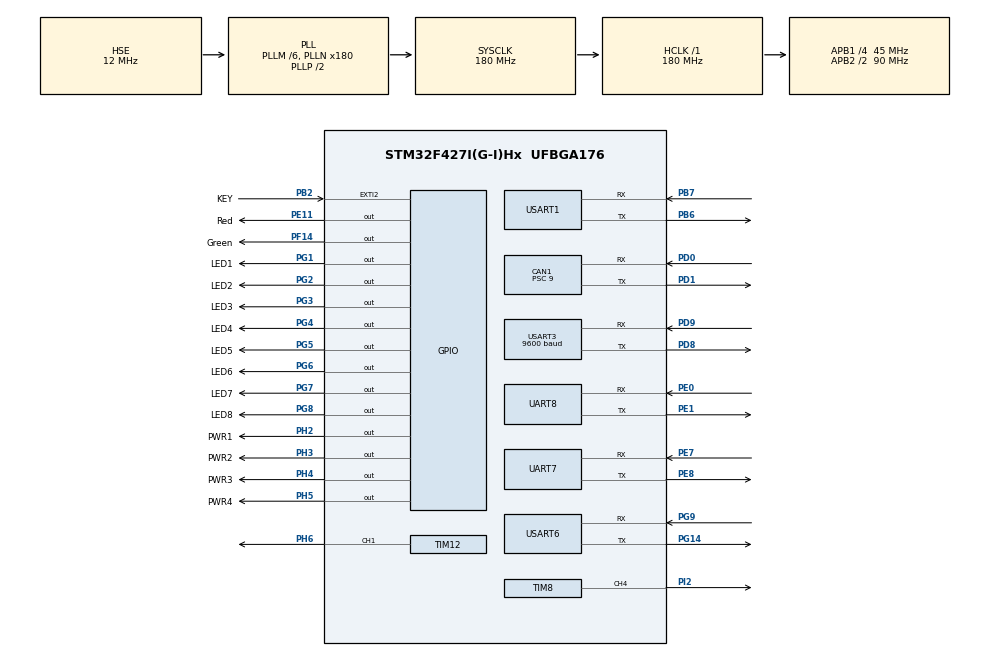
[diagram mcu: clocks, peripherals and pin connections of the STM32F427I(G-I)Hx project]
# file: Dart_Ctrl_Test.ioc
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CAN1.ABOM=ENABLE
CAN1.BS1=CAN_BS1_2TQ
CAN1.BS2=CAN_BS2_2TQ
CAN1.CalculateBaudRate=1000000
CAN1.CalculateTimeBit=1000
CAN1.CalculateTimeQuantum=200.0
CAN1.Prescaler=9
Dma.Request0=UART7_RX
Dma.Request1=UART7_TX
Dma.Request2=USART3_TX
Dma.Request3=USART6_RX
Dma.UART7_RX.0.Direction=DMA_PERIPH_TO_MEMORY
Dma.UART7_RX.0.FIFOMode=DMA_FIFOMODE_DISABLE
Dma.UART7_RX.0.Instance=DMA1_Stream3
Dma.UART7_RX.0.MemDataAlignment=DMA_MDATAALIGN_BYTE
Dma.UART7_RX.0.MemInc=DMA_MINC_ENABLE
Dma.UART7_RX.0.Mode=DMA_NORMAL
Dma.UART7_RX.0.PeriphDataAlignment=DMA_PDATAALIGN_BYTE
Dma.UART7_RX.0.PeriphInc=DMA_PINC_DISABLE
Dma.UART7_RX.0.Priority=DMA_PRIORITY_LOW
Dma.UART7_TX.1.Direction=DMA_MEMORY_TO_PERIPH
Dma.UART7_TX.1.FIFOMode=DMA_FIFOMODE_DISABLE
Dma.UART7_TX.1.Instance=DMA1_Stream1
Dma.UART7_TX.1.MemDataAlignment=DMA_MDATAALIGN_BYTE
Dma.UART7_TX.1.MemInc=DMA_MINC_ENABLE
Dma.UART7_TX.1.Mode=DMA_NORMAL
Dma.UART7_TX.1.PeriphDataAlignment=DMA_PDATAALIGN_BYTE
Dma.UART7_TX.1.PeriphInc=DMA_PINC_DISABLE
Dma.UART7_TX.1.Priority=DMA_PRIORITY_LOW
Dma.USART3_TX.2.Direction=DMA_MEMORY_TO_PERIPH
Dma.USART3_TX.2.FIFOMode=DMA_FIFOMODE_DISABLE
Dma.USART3_TX.2.Instance=DMA1_Stream4
Dma.USART3_TX.2.MemDataAlignment=DMA_MDATAALIGN_BYTE
Dma.USART3_TX.2.MemInc=DMA_MINC_ENABLE
Dma.USART3_TX.2.Mode=DMA_NORMAL
Dma.USART3_TX.2.PeriphDataAlignment=DMA_PDATAALIGN_BYTE
Dma.USART3_TX.2.PeriphInc=DMA_PINC_DISABLE
Dma.USART3_TX.2.Priority=DMA_PRIORITY_LOW
Dma.USART6_RX.3.Direction=DMA_PERIPH_TO_MEMORY
Dma.USART6_RX.3.FIFOMode=DMA_FIFOMODE_DISABLE
Dma.USART6_RX.3.Instance=DMA2_Stream1
Dma.USART6_RX.3.MemDataAlignment=DMA_MDATAALIGN_BYTE
Dma.USART6_RX.3.MemInc=DMA_MINC_ENABLE
Dma.USART6_RX.3.Mode=DMA_NORMAL
Dma.USART6_RX.3.PeriphDataAlignment=DMA_PDATAALIGN_BYTE
Dma.USART6_RX.3.PeriphInc=DMA_PINC_DISABLE
Dma.USART6_RX.3.Priority=DMA_PRIORITY_LOW
FREERTOS.Tasks01=defaultTask,24,128,StartDefaultTask,Default,NULL,Dynamic,NULL,NULL
FREERTOS.configENABLE_FPU=1
Mcu.Family=STM32F4
Mcu.Name=STM32F427I(G-I)Hx
Mcu.Package=UFBGA176
NVIC.CAN1_RX0_IRQn=true\:5\:0\:false\:false\:true\:true\:true\:true\:true
NVIC.CAN1_RX1_IRQn=true\:5\:0\:false\:false\:true\:true\:true\:true\:true
NVIC.CAN1_SCE_IRQn=true\:5\:0\:false\:false\:true\:true\:true\:true\:true
NVIC.CAN1_TX_IRQn=true\:5\:0\:false\:false\:true\:true\:true\:true\:true
NVIC.DMA1_Stream1_IRQn=true\:5\:0\:false\:false\:true\:true\:false\:true\:true
NVIC.DMA1_Stream3_IRQn=true\:5\:0\:false\:false\:true\:true\:false\:true\:true
NVIC.DMA1_Stream4_IRQn=true\:5\:0\:false\:false\:true\:true\:false\:true\:true
NVIC.DMA2_Stream1_IRQn=true\:5\:0\:false\:false\:true\:true\:false\:true\:true
NVIC.PriorityGroup=NVIC_PRIORITYGROUP_4
NVIC.TIM4_IRQn=true\:15\:0\:true\:false\:true\:false\:false\:true\:true
NVIC.TimeBase=TIM4_IRQn
NVIC.TimeBaseIP=TIM4
NVIC.UART7_IRQn=true\:5\:0\:false\:false\:true\:true\:true\:true\:true
NVIC.UART8_IRQn=true\:5\:0\:false\:false\:true\:true\:true\:true\:true
NVIC.USART3_IRQn=true\:5\:0\:false\:false\:true\:true\:true\:true\:true
NVIC.USART6_IRQn=true\:5\:0\:false\:false\:true\:true\:true\:true\:true
PA13.Mode=Serial_Wire
PA13.Signal=SYS_JTMS-SWDIO
PA14.Mode=Serial_Wire
PA14.Signal=SYS_JTCK-SWCLK
PB2/BOOT1.GPIO_Label=KEY
PB2/BOOT1.GPIO_ModeDefaultEXTI=GPIO_MODE_IT_RISING
PB2/BOOT1.GPIO_PuPd=GPIO_PULLDOWN
PB2/BOOT1.Signal=GPXTI2
PB6.Mode=Asynchronous
PB6.Signal=USART1_TX
PB7.Mode=Asynchronous
PB7.Signal=USART1_RX
PC14/OSC32_IN.Mode=LSE-External-Oscillator
PC14/OSC32_IN.Signal=RCC_OSC32_IN
PC15/OSC32_OUT.Mode=LSE-External-Oscillator
PC15/OSC32_OUT.Signal=RCC_OSC32_OUT
PD0.Mode=CAN_Activate
PD0.Signal=CAN1_RX
PD1.Mode=CAN_Activate
PD1.Signal=CAN1_TX
PD8.Mode=Asynchronous
PD8.Signal=USART3_TX
PD9.Mode=Asynchronous
PD9.Signal=USART3_RX
PE0.Mode=Asynchronous
PE0.Signal=UART8_RX
PE1.Mode=Asynchronous
PE1.Signal=UART8_TX
PE11.GPIO_Label=Red
PE11.GPIO_PuPd=GPIO_PULLDOWN
PE11.PinState=GPIO_PIN_SET
PE11.Signal=GPIO_Output
PE7.Mode=Asynchronous
PE7.Signal=UART7_RX
PE8.Mode=Asynchronous
PE8.Signal=UART7_TX
PF14.GPIO_Label=Green
PF14.GPIO_PuPd=GPIO_PULLDOWN
PF14.GPIO_Speed=GPIO_SPEED_FREQ_LOW
PF14.PinState=GPIO_PIN_SET
PF14.Signal=GPIO_Output
PG1.GPIO_Label=LED1
PG1.GPIO_PuPd=GPIO_PULLDOWN
PG1.PinState=GPIO_PIN_SET
PG1.Signal=GPIO_Output
PG14.Mode=Asynchronous
PG14.Signal=USART6_TX
PG2.GPIO_Label=LED2
PG2.GPIO_PuPd=GPIO_PULLDOWN
PG2.PinState=GPIO_PIN_SET
PG2.Signal=GPIO_Output
PG3.GPIO_Label=LED3
PG3.GPIO_PuPd=GPIO_PULLDOWN
PG3.PinState=GPIO_PIN_SET
PG3.Signal=GPIO_Output
PG4.GPIO_Label=LED4
PG4.GPIO_PuPd=GPIO_PULLDOWN
PG4.PinState=GPIO_PIN_SET
PG4.Signal=GPIO_Output
PG5.GPIO_Label=LED5
PG5.GPIO_PuPd=GPIO_PULLDOWN
PG5.PinState=GPIO_PIN_SET
PG5.Signal=GPIO_Output
PG6.GPIO_Label=LED6
PG6.GPIO_PuPd=GPIO_PULLDOWN
PG6.PinState=GPIO_PIN_SET
PG6.Signal=GPIO_Output
PG7.GPIO_Label=LED7
PG7.GPIO_PuPd=GPIO_PULLDOWN
PG7.PinState=GPIO_PIN_SET
PG7.Signal=GPIO_Output
PG8.GPIO_Label=LED8
PG8.GPIO_PuPd=GPIO_PULLDOWN
PG8.PinState=GPIO_PIN_SET
PG8.Signal=GPIO_Output
PG9.Mode=Asynchronous
PG9.Signal=USART6_RX
PH0/OSC_IN.Mode=HSE-External-Oscillator
PH0/OSC_IN.Signal=RCC_OSC_IN
PH1/OSC_OUT.Mode=HSE-External-Oscillator
PH1/OSC_OUT.Signal=RCC_OSC_OUT
PH2.GPIO_Label=PWR1
PH2.GPIO_ModeDefaultOutputPP=GPIO_MODE_OUTPUT_PP
PH2.GPIO_PuPd=GPIO_PULLDOWN
PH2.Signal=GPIO_Output
PH3.GPIO_Label=PWR2
PH3.GPIO_PuPd=GPIO_PULLDOWN
PH3.Signal=GPIO_Output
PH4.GPIO_Label=PWR3
PH4.GPIO_PuPd=GPIO_PULLDOWN
PH4.Signal=GPIO_Output
PH5.GPIO_Label=PWR4
PH5.GPIO_PuPd=GPIO_PULLDOWN
PH5.Signal=GPIO_Output
PH6.Signal=S_TIM12_CH1
PI2.Signal=S_TIM8_CH4
ProjectManager.HeapSize=0x200
ProjectManager.StackSize=0x400
ProjectManager.TargetToolchain=MDK-ARM V5.32
RCC.48MHZClocksFreq_Value=90000000
RCC.AHBFreq_Value=180000000
RCC.APB1CLKDivider=RCC_HCLK_DIV4
RCC.APB1Freq_Value=45000000
RCC.APB1TimFreq_Value=90000000
RCC.APB2CLKDivider=RCC_HCLK_DIV2
RCC.APB2Freq_Value=90000000
RCC.APB2TimFreq_Value=180000000
RCC.CortexFreq_Value=180000000
RCC.HCLKFreq_Value=180000000
RCC.HSE_VALUE=12000000
RCC.HSI_VALUE=16000000
RCC.PLLM=6
RCC.PLLN=180
RCC.PLLSourceVirtual=RCC_PLLSOURCE_HSE
RCC.SYSCLKFreq_VALUE=180000000
RCC.SYSCLKSource=RCC_SYSCLKSOURCE_PLLCLK
RCC.VCOOutputFreq_Value=360000000
SH.S_TIM12_CH1.0=TIM12_CH1,PWM Generation1 CH1
SH.S_TIM8_CH4.0=TIM8_CH4,PWM Generation4 CH4
TIM12.AutoReloadPreload=TIM_AUTORELOAD_PRELOAD_ENABLE
TIM12.Channel-PWM\ Generation1\ CH1=TIM_CHANNEL_1
TIM12.Period=9000 - 1
TIM12.Pulse-PWM\ Generation1\ CH1=2699
TIM8.AutoReloadPreload=TIM_AUTORELOAD_PRELOAD_ENABLE
TIM8.Channel-PWM\ Generation4\ CH4=TIM_CHANNEL_4
TIM8.Period=20000 - 1
TIM8.Prescaler=180 - 1
TIM8.Pulse-PWM\ Generation4\ CH4=500
UART7.VirtualMode=Asynchronous
UART8.VirtualMode=Asynchronous
USART1.VirtualMode=VM_ASYNC
USART3.BaudRate=9600
USART3.VirtualMode=VM_ASYNC
USART6.VirtualMode=VM_ASYNC
VP_FREERTOS_VS_CMSIS_V2.Mode=CMSIS_V2
VP_SYS_VS_tim4.Mode=TIM4
VP_TIM12_VS_ClockSourceINT.Mode=Internal
VP_TIM8_VS_ClockSourceINT.Mode=Internal
board=custom

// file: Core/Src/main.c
/* USER CODE BEGIN Header */
/**
 ******************************************************************************
 * @file           : main.c
 * @brief          : Main program body
 ******************************************************************************
 * @attention
 *
 * Copyright (c) 2025 STMicroelectronics.
 * All rights reserved.
 *
 * This software is licensed under terms that can be found in the LICENSE file
 * in the root directory of this software component.
 * If no LICENSE file comes with this software, it is provided AS-IS.
 *
 ******************************************************************************
 */
/* USER CODE END Header */
#include "main.h"
#include "cmsis_os.h"
#include "can.h"
#include "dma.h"
#include "tim.h"
#include "usart.h"
#include "gpio.h"

/* USER CODE BEGIN Includes */
#include "UserTask.h"
/* USER CODE END Includes */

void SystemClock_Config(void);
void MX_FREERTOS_Init(void);

int main(void)
{

  /* MCU Configuration--------------------------------------------------------*/

  /* Reset of all peripherals, Initializes the Flash interface and the Systick. */
  HAL_Init();

  /* Configure the system clock */
  SystemClock_Config();

  /* Initialize all configured peripherals */
  MX_GPIO_Init();
  MX_DMA_Init();
  MX_CAN1_Init();
  MX_UART7_Init();
  MX_USART3_UART_Init();
  MX_USART6_UART_Init();
  MX_UART8_Init();
  MX_TIM12_Init();
  MX_USART1_UART_Init();
  MX_TIM8_Init();
  /* USER CODE BEGIN 2 */

  // 对各个外设进行初始化
  Module_Init();

  /* USER CODE END 2 */

  /* Init scheduler */
  osKernelInitialize();  /* Call init function for freertos objects (in cmsis_os2.c) */
  MX_FREERTOS_Init();

  /* Start scheduler */
  osKernelStart();

  /* We should never get here as control is now taken by the scheduler */

  /* Infinite loop */
  while (1)
  {

  }
}

void SystemClock_Config(void)
{
  RCC_OscInitTypeDef RCC_OscInitStruct = {0};
  RCC_ClkInitTypeDef RCC_ClkInitStruct = {0};

  /** Configure the main internal regulator output voltage
  */
  __HAL_RCC_PWR_CLK_ENABLE();
  __HAL_PWR_VOLTAGESCALING_CONFIG(PWR_REGULATOR_VOLTAGE_SCALE1);

  /** Initializes the RCC Oscillators according to the specified parameters
  * in the RCC_OscInitTypeDef structure.
  */
  RCC_OscInitStruct.OscillatorType = RCC_OSCILLATORTYPE_HSE;
  RCC_OscInitStruct.HSEState = RCC_HSE_ON;
  RCC_OscInitStruct.PLL.PLLState = RCC_PLL_ON;
  RCC_OscInitStruct.PLL.PLLSource = RCC_PLLSOURCE_HSE;
  RCC_OscInitStruct.PLL.PLLM = 6;
  RCC_OscInitStruct.PLL.PLLN = 180;
  RCC_OscInitStruct.PLL.PLLP = RCC_PLLP_DIV2;
  RCC_OscInitStruct.PLL.PLLQ = 4;
  if (HAL_RCC_OscConfig(&RCC_OscInitStruct) != HAL_OK)
  {
    Error_Handler();
  }

  /** Activate the Over-Drive mode
  */
  if (HAL_PWREx_EnableOverDrive() != HAL_OK)
  {
    Error_Handler();
  }

  /** Initializes the CPU, AHB and APB buses clocks
  */
  RCC_ClkInitStruct.ClockType = RCC_CLOCKTYPE_HCLK|RCC_CLOCKTYPE_SYSCLK
                              |RCC_CLOCKTYPE_PCLK1|RCC_CLOCKTYPE_PCLK2;
  RCC_ClkInitStruct.SYSCLKSource = RCC_SYSCLKSOURCE_PLLCLK;
  RCC_ClkInitStruct.AHBCLKDivider = RCC_SYSCLK_DIV1;
  RCC_ClkInitStruct.APB1CLKDivider = RCC_HCLK_DIV4;
  RCC_ClkInitStruct.APB2CLKDivider = RCC_HCLK_DIV2;

  if (HAL_RCC_ClockConfig(&RCC_ClkInitStruct, FLASH_LATENCY_5) != HAL_OK)
  {
    Error_Handler();
  }
}

void HAL_TIM_PeriodElapsedCallback(TIM_HandleTypeDef *htim)
{
  if (htim->Instance == TIM4)
  {
    HAL_IncTick();
  }
}

void Error_Handler(void)
{
  __disable_irq();
  while (1)
  {
  }
}

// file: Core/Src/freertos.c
/* USER CODE BEGIN Header */
/**
 ******************************************************************************
 * File Name          : freertos.c
 * Description        : Code for freertos applications
 ******************************************************************************
 * @attention
 *
 * Copyright (c) 2025 STMicroelectronics.
 * All rights reserved.
 *
 * This software is licensed under terms that can be found in the LICENSE file
 * in the root directory of this software component.
 * If no LICENSE file comes with this software, it is provided AS-IS.
 *
 ******************************************************************************
 */
/* USER CODE END Header */

#include "FreeRTOS.h"
#include "task.h"
#include "main.h"
#include "cmsis_os.h"

/* USER CODE BEGIN Includes */
#include "UserTask.h"
#include <stdio.h>
#include <string.h>
#include "config.h"
/* USER CODE END Includes */

/* USER CODE BEGIN Variables */

// float Target = 400.0f; // 360° * 19.2 (度数 * 减速比)| 360 * 36.0(度数 * 减速比) 12960
// static uint32_t lastServoTime = 0;
// float frequence = 0.0f;
// float time = 0.0f;

// static StackType_t g_pxChangeTarget[128];
// static StaticTask_t g_TCBChangeTarget;
// static TaskHandle_t g_HandleChangeTarget;

// uint16_t Gripper1Angle = 0;
// uint16_t Gripper2Angle = 0;
// uint16_t Gripper3Angle = 0;

static StaticSemaphore_t g_xRmBufferMutexBuffer;
SemaphoreHandle_t g_xRmBufferMutexHandle;

/// @brief 改变电机目标数值
/// @param arg 任务参数（未使用）
/// @return 无
// void pxChangeTarget(void *arg)
// {
//   (void)arg; // 消除未使用参数警告
//   vTaskDelay(20);
//   while (1)
//   {
//     vTaskDelay(1500);
//     if (Target < 500.0f)
//     {
//       Target += 100.0f;
//     }
//     else
//     {
//       Target = 0.0f;
//       vTaskDelay(4000);
//     }
//   }
// }

/* USER CODE END Variables */
/* Definitions for defaultTask */
osThreadId_t defaultTaskHandle;
const osThreadAttr_t defaultTask_attributes = {
    .name = "defaultTask",
    .stack_size = 128 * 4,
    .priority = (osPriority_t)osPriorityNormal,
};

void StartDefaultTask(void *argument);

void MX_FREERTOS_Init(void); /* (MISRA C 2004 rule 8.1) */

void MX_FREERTOS_Init(void)
{

  /* USER CODE BEGIN RTOS_MUTEX */
  /* add mutexes, ... */
  g_xRmBufferMutexHandle = xSemaphoreCreateMutexStatic(&g_xRmBufferMutexBuffer);
  /* USER CODE END RTOS_MUTEX */

  /* Create the thread(s) */
  /* creation of defaultTask */
  defaultTaskHandle = osThreadNew(StartDefaultTask, NULL, &defaultTask_attributes);

  /* USER CODE BEGIN RTOS_THREADS */
  /* add threads, ... */

  // 改变电机目标数值的一个乐色任务
  // g_HandleChangeTarget = xTaskCreateStatic(pxChangeTarget, "ChangeTarget", 128, NULL, osPriorityNormal, g_pxChangeTarget, &g_TCBChangeTarget);

  // 飞镖任务初始化
  TaskInitFunc();

  /* USER CODE END RTOS_THREADS */

}

void StartDefaultTask(void *argument)
{
  /* USER CODE BEGIN StartDefaultTask */

  // 定义数据包接收变量（无需手动初始化，UART_GetServoPacket会完全覆盖）
  //  ServoPacket_t HxFb;
  //  DartPacket_t UpcFb;

  // 舵机初始化（只调用一次，在循环外）
  //  ServoInit();
  //  vTaskDelay(100); // 等待初始化完成
  //  uint8_t servo_ids[3] = {0x01, 0x02, 0x03};
  //  uint16_t angles[3] = {0, 0, 0};
  //  uint16_t data[3] = {375, 375, 375};
  //  ServoControlPos(3, 375, 1000);
  //  vTaskDelay(1);
  //  ServoControlPos(2, 375, 1000);
  //  vTaskDelay(1);
  //  ServoControlPos(1, 375, 1000);
  //  vTaskDelay(2000);
  //  ServoControlMulti(3, servo_ids, angles, 1000);
  // uint32_t last_cnt = 0x0000;
  // float dt = 0.0f;
  // uint8_t test = 0;
  // float offset_angle = MotorManager.MotorList[RM_3508_GRIPPER - 1].motor_data.offset_ecd_angle;
  // bool temp = true;
  // DWT_GetDeltaT(&last_cnt);
  // uint32_t b = 0;
  // b = HAL_GetTick();
  // while (temp)
  // {
  //   DM_Motor_RefreshData(DM_4310_YAW);
  //   if (b + 1000 < HAL_GetTick())
  //   {
  //     temp = false;
  //   }
  // }
  /* Infinite loop */
  for (;;)
  {
    // 中期文档测量
    /* 1.RM3508所在换弹程序的时长以及曲线 */
    /* 3508PID响应曲线 */
    /* 基于飞镖换弹的阶跃响应 */
    // RmMotorPID_Calc(RM_3508_GRIPPER, Target);
    // dt = DWT_GetDeltaT(&last_cnt);
    // frequence = 1.0f / dt;

    /* 飞镖换弹的实际任务测试频率 */
    // for (uint8_t a = 0; a < 3; a++)
    // {
    //   if (a == 0)
    //   {
    //     Target = FirstServoLoc;
    //     Gripper1Angle = 375;
    //   }
    //   else if (a == 1)
    //   {
    //     Target = SecondServoLoc;
    //     Gripper1Angle = 375;
    //   }
    //   else
    //   {
    //     Target = ThirdServoLoc;
    //     Gripper3Angle = 375;
    //   }
    //   while (!IS_IN_DEADZONE(Motor_GetTotalAngle(RM_3508_GRIPPER), Target, MOTOR_DEAD_ZONE))
    //   {
    //     RmMotorPID_Calc(RM_3508_GRIPPER, Target);
    //   }
    //   CASCADE_PID_Clear_Integral(&MotorManager.MotorList[RM_3508_GRIPPER - 1].cascade_pid);
    //   float GripperTarget = offset_angle;
    //   float MotorData = Motor_GetTotalAngle(RM_3508_GRIPPER);
    // while (!IS_IN_DEADZONE(MotorData, 0.0f, MOTOR_DEAD_ZONE))
    //   {
    //     RmMotorPID_Calc(RM_3508_GRIPPER, GripperTarget);
    //     MotorData = Motor_GetTotalAngle(RM_3508_GRIPPER);
    //   }
    // 	osDelay(310);
    //   dt = DWT_GetDeltaT(&last_cnt);
    //   time = 1.0f / dt;
    // }
    /* 2.RM2006所在的扳机响应时长以及曲线 */
    // RmMotorPID_Calc(RM_2006_TRIGGER, Target);
    // dt = DWT_GetDeltaT(&last_cnt);
    // frequence = 1.0f / dt;

    /* 3.云台电机响应时长以及曲线 */
    // float degree = 0.0f;
    // DmMotorSendCfg(DM_4310_YAW, Target, 0.0f, DM_MIT); // 调节Yaw轴位置
    // degree = Motor_GetTotalAngle(DM_4310_YAW);
    // printf("torque=%f,target=%f,feedback=%f,", MotorManager.MotorList[4].motor_data.solved_data[2], Target, degree);
    // vTaskDelay(3);
    // dt = DWT_GetDeltaT(&last_cnt);
    // frequence = 1.0f / dt;
    // while (degree = Motor_GetTotalAngle(DM_4310_YAW), !IS_IN_DEADZONE(degree, Target, 1.0f))
    // {
    //   DM_Motor_RefreshData(DM_4310_YAW);
    //   vTaskDelay(1);
    //   temp = true;
    // }
    // if (temp)
    // {
    //   time = dt;
    //   temp = false;
    // 	b = HAL_GetTick();
    // }
    // if (b + 1000 < HAL_GetTick())
    // {
    // 	Target = 0.0f;
    // }
    /* 4.储能电机对应的位置响应以及力矩响应 */

    // static float last_target = 0.0f;
    // static float start_time = 0.0f;
    // if (Target != last_target)
    // {
    //   last_target = Target;
    //   start_time = DWT_GetTimeline_ms();
    // }
    // float degree = 0.0f;
    // DmMotorSendCfg(DM_3519_STRENTH_LEFT, -Target, 5.0f, DM_LOCATION_SPEED);
    // DmMotorSendCfg(DM_3519_STRENTH_RIGHT, Target, 5.0f, DM_LOCATION_SPEED);
    // if (IS_IN_DEADZONE(-MotorManager.MotorList[2].motor_data.solved_data[0], Target, 1.0f))
    // {
    //   if (Target < 500.0f)
    //   {
    //     Target += 100.0f;
    //   }
    //   else
    //   {
    //     Target = 0.0f;
    //     vTaskDelay(4000);
    //   }
    //   dt = DWT_GetDeltaT(&last_cnt);
    //   frequence = 1.0f / dt;
    // }
    // printf("leftAngle=%.1f,rightAngle=%.1f,target=%.1f,feedback=%.1f,leftTorque=%.1f,rightTorque=%.1f,", -MotorManager.MotorList[2].motor_data.solved_data[0], MotorManager.MotorList[3].motor_data.solved_data[0], Target, degree, -MotorManager.MotorList[2].motor_data.solved_data[2], MotorManager.MotorList[3].motor_data.solved_data[2]);
    // vTaskDelay(1);

    // RmMotorPID_Calc(RM_2006_TRIGGER, Target);
    // RmMotorSendCfg(RM_2006_TRIGGER, 1000);
    HAL_GPIO_TogglePin(Green_GPIO_Port, Green_Pin);
    vTaskDelay(250);
  }
  /* USER CODE END StartDefaultTask */
}
